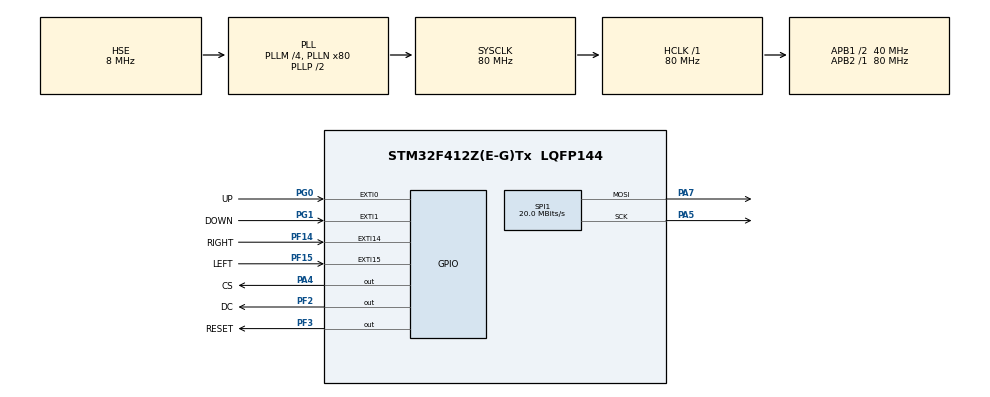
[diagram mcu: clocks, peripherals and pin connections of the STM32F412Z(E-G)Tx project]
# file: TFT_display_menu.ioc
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Dma.Request0=SPI1_TX
Dma.SPI1_TX.0.Direction=DMA_MEMORY_TO_PERIPH
Dma.SPI1_TX.0.FIFOMode=DMA_FIFOMODE_DISABLE
Dma.SPI1_TX.0.Instance=DMA2_Stream2
Dma.SPI1_TX.0.MemDataAlignment=DMA_MDATAALIGN_BYTE
Dma.SPI1_TX.0.MemInc=DMA_MINC_ENABLE
Dma.SPI1_TX.0.Mode=DMA_NORMAL
Dma.SPI1_TX.0.PeriphDataAlignment=DMA_PDATAALIGN_BYTE
Dma.SPI1_TX.0.PeriphInc=DMA_PINC_DISABLE
Dma.SPI1_TX.0.Priority=DMA_PRIORITY_LOW
Mcu.Family=STM32F4
Mcu.Name=STM32F412Z(E-G)Tx
Mcu.Package=LQFP144
NVIC.DMA2_Stream2_IRQn=true\:0\:0\:false\:false\:true\:false\:true\:true
NVIC.PriorityGroup=NVIC_PRIORITYGROUP_4
NVIC.SPI1_IRQn=true\:0\:0\:false\:false\:true\:true\:true\:true
NVIC.TIM2_IRQn=true\:15\:0\:false\:false\:true\:false\:true\:true
NVIC.TimeBase=TIM2_IRQn
NVIC.TimeBaseIP=TIM2
PA4.GPIO_Label=CS
PA4.Signal=GPIO_Output
PA5.Mode=TX_Only_Simplex_Unidirect_Master
PA5.Signal=SPI1_SCK
PA7.Mode=TX_Only_Simplex_Unidirect_Master
PA7.Signal=SPI1_MOSI
PF14.GPIO_Label=RIGHT
PF14.GPIO_ModeDefaultEXTI=GPIO_MODE_IT_FALLING
PF14.GPIO_PuPd=GPIO_PULLDOWN
PF14.Signal=GPXTI14
PF15.GPIO_Label=LEFT
PF15.GPIO_ModeDefaultEXTI=GPIO_MODE_IT_FALLING
PF15.GPIO_PuPd=GPIO_PULLDOWN
PF15.Signal=GPXTI15
PF2.GPIO_Label=DC
PF2.Signal=GPIO_Output
PF3.GPIO_Label=RESET
PF3.Signal=GPIO_Output
PG0.GPIO_Label=UP
PG0.GPIO_ModeDefaultEXTI=GPIO_MODE_IT_FALLING
PG0.GPIO_PuPd=GPIO_PULLDOWN
PG0.Signal=GPXTI0
PG1.GPIO_Label=DOWN
PG1.GPIO_ModeDefaultEXTI=GPIO_MODE_IT_FALLING
PG1.GPIO_PuPd=GPIO_PULLDOWN
PG1.Signal=GPXTI1
PH0\ -\ OSC_IN.Mode=HSE-External-Oscillator
PH0\ -\ OSC_IN.Signal=RCC_OSC_IN
PH1\ -\ OSC_OUT.Mode=HSE-External-Oscillator
PH1\ -\ OSC_OUT.Signal=RCC_OSC_OUT
ProjectManager.HeapSize=0x200
ProjectManager.StackSize=0x400
ProjectManager.TargetToolchain=STM32CubeIDE
RCC.AHBFreq_Value=80000000
RCC.APB1CLKDivider=RCC_HCLK_DIV2
RCC.APB1Freq_Value=40000000
RCC.APB1TimFreq_Value=80000000
RCC.APB2Freq_Value=80000000
RCC.APB2TimFreq_Value=80000000
RCC.CortexFreq_Value=80000000
RCC.HCLKFreq_Value=80000000
RCC.HSE_VALUE=8000000
RCC.PLLM=4
RCC.PLLN=80
RCC.PLLSourceVirtual=RCC_PLLSOURCE_HSE
RCC.SYSCLKFreq_VALUE=80000000
RCC.SYSCLKSource=RCC_SYSCLKSOURCE_PLLCLK
RCC.USBFreq_Value=80000000
RCC.VCOOutputFreq_Value=160000000
SPI1.BaudRatePrescaler=SPI_BAUDRATEPRESCALER_4
SPI1.CalculateBaudRate=20.0 MBits/s
SPI1.Direction=SPI_DIRECTION_2LINES
SPI1.Mode=SPI_MODE_MASTER
SPI1.VirtualType=VM_MASTER
VP_SYS_VS_tim2.Mode=TIM2
board=custom

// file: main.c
/* USER CODE BEGIN Header */
/**
  ******************************************************************************
  * @file           : main.c
  * @brief          : Main program body
  ******************************************************************************
  * @attention
  *
  * Copyright (c) 2025 STMicroelectronics.
  * All rights reserved.
  *
  * This software is licensed under terms that can be found in the LICENSE file
  * in the root directory of this software component.
  * If no LICENSE file comes with this software, it is provided AS-IS.
  *
  ******************************************************************************
  */
/* USER CODE END Header */
#include "main.h"

/* USER CODE BEGIN Includes */
#include "lvgl.h"
#include "LCDController.h"
#include "ili9341.h"
#include "ui.h"
#include "screens.h"
/* USER CODE END Includes */

SPI_HandleTypeDef hspi1;
DMA_HandleTypeDef hdma_spi1_tx;

void SystemClock_Config(void);
static void MX_GPIO_Init(void);
static void MX_DMA_Init(void);
static void MX_SPI1_Init(void);

int main(void)
{

  /* MCU Configuration--------------------------------------------------------*/

  /* Reset of all peripherals, Initializes the Flash interface and the Systick. */
  HAL_Init();

  /* Configure the system clock */
  SystemClock_Config();

  /* Initialize all configured peripherals */
  MX_GPIO_Init();
  MX_DMA_Init();
  MX_SPI1_Init();
  /* USER CODE BEGIN 2 */
  lv_init();
  lv_port_disp_init();
  ui_init();

  //lv_obj_set_style_bg_color(lv_scr_act(), lv_color_hex(0x0000FF), LV_PART_MAIN);
  //lv_obj_set_style_text_color(lv_scr_act(), lv_color_hex(0xffffff), LV_PART_MAIN);

  //create_menu_screen();
//  lv_obj_t * label = lv_label_create(lv_scr_act());
//  lv_label_set_text(label, "Hello");
//  lv_obj_align(label, LV_ALIGN_CENTER, 0, 0);  // Align to center
  /* USER CODE END 2 */

  /* Infinite loop */
  while (1)
  {

    /* USER CODE BEGIN 3 */
	  lv_timer_handler();
	  HAL_Delay(5);
  }
  /* USER CODE END 3 */
}

void SystemClock_Config(void)
{
  RCC_OscInitTypeDef RCC_OscInitStruct = {0};
  RCC_ClkInitTypeDef RCC_ClkInitStruct = {0};

  /** Configure the main internal regulator output voltage
  */
  __HAL_RCC_PWR_CLK_ENABLE();
  __HAL_PWR_VOLTAGESCALING_CONFIG(PWR_REGULATOR_VOLTAGE_SCALE1);

  /** Initializes the RCC Oscillators according to the specified parameters
  * in the RCC_OscInitTypeDef structure.
  */
  RCC_OscInitStruct.OscillatorType = RCC_OSCILLATORTYPE_HSE;
  RCC_OscInitStruct.HSEState = RCC_HSE_ON;
  RCC_OscInitStruct.PLL.PLLState = RCC_PLL_ON;
  RCC_OscInitStruct.PLL.PLLSource = RCC_PLLSOURCE_HSE;
  RCC_OscInitStruct.PLL.PLLM = 4;
  RCC_OscInitStruct.PLL.PLLN = 80;
  RCC_OscInitStruct.PLL.PLLP = RCC_PLLP_DIV2;
  RCC_OscInitStruct.PLL.PLLQ = 2;
  RCC_OscInitStruct.PLL.PLLR = 2;
  if (HAL_RCC_OscConfig(&RCC_OscInitStruct) != HAL_OK)
  {
    Error_Handler();
  }

  /** Initializes the CPU, AHB and APB buses clocks
  */
  RCC_ClkInitStruct.ClockType = RCC_CLOCKTYPE_HCLK|RCC_CLOCKTYPE_SYSCLK
                              |RCC_CLOCKTYPE_PCLK1|RCC_CLOCKTYPE_PCLK2;
  RCC_ClkInitStruct.SYSCLKSource = RCC_SYSCLKSOURCE_PLLCLK;
  RCC_ClkInitStruct.AHBCLKDivider = RCC_SYSCLK_DIV1;
  RCC_ClkInitStruct.APB1CLKDivider = RCC_HCLK_DIV2;
  RCC_ClkInitStruct.APB2CLKDivider = RCC_HCLK_DIV1;

  if (HAL_RCC_ClockConfig(&RCC_ClkInitStruct, FLASH_LATENCY_2) != HAL_OK)
  {
    Error_Handler();
  }
}

static void MX_SPI1_Init(void)
{

  /* SPI1 parameter configuration*/
  hspi1.Instance = SPI1;
  hspi1.Init.Mode = SPI_MODE_MASTER;
  hspi1.Init.Direction = SPI_DIRECTION_2LINES;
  hspi1.Init.DataSize = SPI_DATASIZE_8BIT;
  hspi1.Init.CLKPolarity = SPI_POLARITY_LOW;
  hspi1.Init.CLKPhase = SPI_PHASE_1EDGE;
  hspi1.Init.NSS = SPI_NSS_SOFT;
  hspi1.Init.BaudRatePrescaler = SPI_BAUDRATEPRESCALER_4;
  hspi1.Init.FirstBit = SPI_FIRSTBIT_MSB;
  hspi1.Init.TIMode = SPI_TIMODE_DISABLE;
  hspi1.Init.CRCCalculation = SPI_CRCCALCULATION_DISABLE;
  hspi1.Init.CRCPolynomial = 10;
  if (HAL_SPI_Init(&hspi1) != HAL_OK)
  {
    Error_Handler();
  }

}

static void MX_DMA_Init(void)
{

  /* DMA controller clock enable */
  __HAL_RCC_DMA2_CLK_ENABLE();

  /* DMA interrupt init */
  /* DMA2_Stream2_IRQn interrupt configuration */
  HAL_NVIC_SetPriority(DMA2_Stream2_IRQn, 0, 0);
  HAL_NVIC_EnableIRQ(DMA2_Stream2_IRQn);

}

static void MX_GPIO_Init(void)
{
  GPIO_InitTypeDef GPIO_InitStruct = {0};

  /* GPIO Ports Clock Enable */
  __HAL_RCC_GPIOF_CLK_ENABLE();
  __HAL_RCC_GPIOH_CLK_ENABLE();
  __HAL_RCC_GPIOA_CLK_ENABLE();
  __HAL_RCC_GPIOG_CLK_ENABLE();

  /*Configure GPIO pin Output Level */
  HAL_GPIO_WritePin(GPIOF, DC_Pin|RESET_Pin, GPIO_PIN_RESET);

  /*Configure GPIO pin Output Level */
  HAL_GPIO_WritePin(CS_GPIO_Port, CS_Pin, GPIO_PIN_RESET);

  /*Configure GPIO pins : DC_Pin RESET_Pin */
  GPIO_InitStruct.Pin = DC_Pin|RESET_Pin;
  GPIO_InitStruct.Mode = GPIO_MODE_OUTPUT_PP;
  GPIO_InitStruct.Pull = GPIO_NOPULL;
  GPIO_InitStruct.Speed = GPIO_SPEED_FREQ_LOW;
  HAL_GPIO_Init(GPIOF, &GPIO_InitStruct);

  /*Configure GPIO pin : CS_Pin */
  GPIO_InitStruct.Pin = CS_Pin;
  GPIO_InitStruct.Mode = GPIO_MODE_OUTPUT_PP;
  GPIO_InitStruct.Pull = GPIO_NOPULL;
  GPIO_InitStruct.Speed = GPIO_SPEED_FREQ_LOW;
  HAL_GPIO_Init(CS_GPIO_Port, &GPIO_InitStruct);

  /*Configure GPIO pins : RIGHT_Pin LEFT_Pin */
  GPIO_InitStruct.Pin = RIGHT_Pin|LEFT_Pin;
  GPIO_InitStruct.Mode = GPIO_MODE_IT_FALLING;
  GPIO_InitStruct.Pull = GPIO_PULLDOWN;
  HAL_GPIO_Init(GPIOF, &GPIO_InitStruct);

  /*Configure GPIO pins : UP_Pin DOWN_Pin */
  GPIO_InitStruct.Pin = UP_Pin|DOWN_Pin;
  GPIO_InitStruct.Mode = GPIO_MODE_IT_FALLING;
  GPIO_InitStruct.Pull = GPIO_PULLDOWN;
  HAL_GPIO_Init(GPIOG, &GPIO_InitStruct);

}

void HAL_TIM_PeriodElapsedCallback(TIM_HandleTypeDef *htim)
{
  if (htim->Instance == TIM2)
  {
    HAL_IncTick();
  }
}

void Error_Handler(void)
{
  __disable_irq();
  while (1)
  {
  }
}
